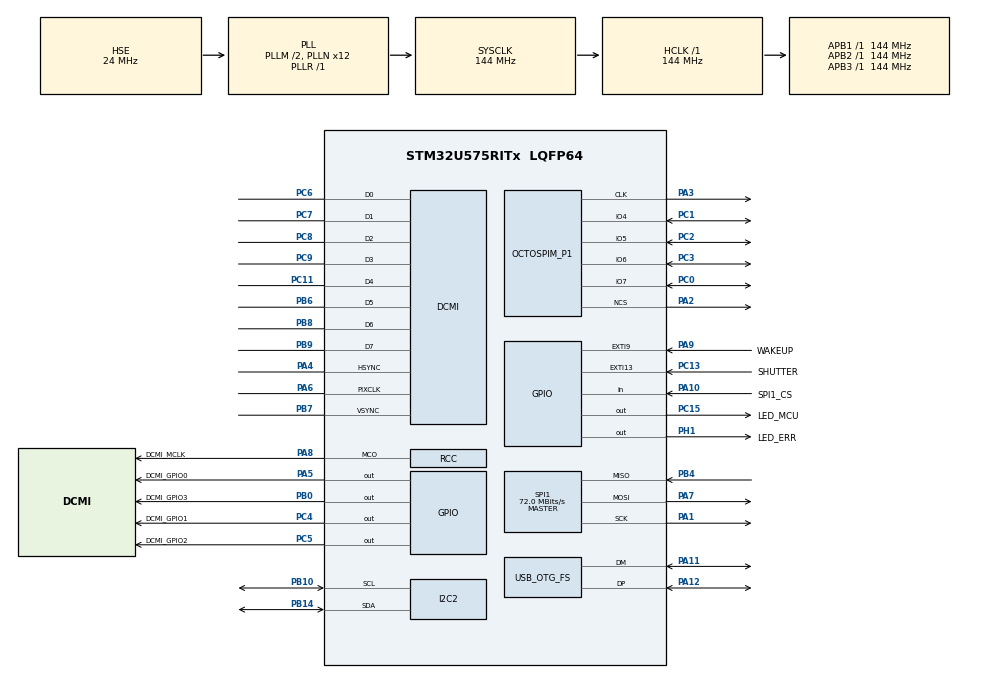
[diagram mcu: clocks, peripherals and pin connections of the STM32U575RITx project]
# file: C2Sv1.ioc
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CORTEX_M33_NS.userName=CORTEX_M33
DCMI.HSPolarity=DCMI_HSPOLARITY_LOW
DCMI.JPEGMode=DCMI_JPEG_DISABLE
DCMI.PCKPolarity=DCMI_PCKPOLARITY_RISING
DCMI.VSPolarity=DCMI_VSPOLARITY_HIGH
GPDMA1.ChannelPRIV_GPDMACH0=DMA_CHANNEL_NPRIV
GPDMA1.LINKALLOCATEDPORT_GPDMACH0=DMA_LINK_ALLOCATED_PORT0
GPDMA1.LINKEDLISTMODE_GPDMACH0=DMA_LINKEDLIST_CIRCULAR
GPDMA1.PRIORITY_LL_GPDMACH0=DMA_HIGH_PRIORITY
GPDMA1.RECAP_GPDMACH0=DMA_REQUEST_DCMI
I2C2.NoStretchMode=I2C_NOSTRETCH_ENABLE
I2C2.Timing=0x20B0D9FF
Linkedlist.MDMA_Channel0.GP_SW.0.BlkHWRequest=DMA_BREQ_SINGLE_BURST
Linkedlist.MDMA_Channel0.GP_SW.0.DataHandling=NONE
Linkedlist.MDMA_Channel0.GP_SW.0.DataSize=0
Linkedlist.MDMA_Channel0.GP_SW.0.DestBurstLength=1
Linkedlist.MDMA_Channel0.GP_SW.0.DestDataWidth=DMA_DEST_DATAWIDTH_WORD
Linkedlist.MDMA_Channel0.GP_SW.0.DestInc=DMA_DINC_INCREMENTED
Linkedlist.MDMA_Channel0.GP_SW.0.Direction=DMA_PERIPH_TO_MEMORY
Linkedlist.MDMA_Channel0.GP_SW.0.DstAddress=0
Linkedlist.MDMA_Channel0.GP_SW.0.Instance=MDMA_Channel0
Linkedlist.MDMA_Channel0.GP_SW.0.LL_CIRCULARNODE=DCMI_Node1
Linkedlist.MDMA_Channel0.GP_SW.0.LL_MASTERDMA=GPDMA
Linkedlist.MDMA_Channel0.GP_SW.0.LL_NAME=DCMIQueue
Linkedlist.MDMA_Channel0.GP_SW.0.LL_TYPE=CIRCULAR
Linkedlist.MDMA_Channel0.GP_SW.0.NODE_NAME=DCMI_Node1
Linkedlist.MDMA_Channel0.GP_SW.0.Requestforcodegen=GPDMA1_REQUEST_DCMI
Linkedlist.MDMA_Channel0.GP_SW.0.SrcAddress=0
Linkedlist.MDMA_Channel0.GP_SW.0.SrcBurstLength=1
Linkedlist.MDMA_Channel0.GP_SW.0.SrcDataWidth=DMA_SRC_DATAWIDTH_WORD
Linkedlist.MDMA_Channel0.GP_SW.0.SrcInc=DMA_SINC_FIXED
Linkedlist.MDMA_Channel0.GP_SW.0.TransferAllocatedPortDest=DMA_DEST_ALLOCATED_PORT0
Linkedlist.MDMA_Channel0.GP_SW.0.TransferAllocatedPortSrc=DMA_SRC_ALLOCATED_PORT0
Linkedlist.MDMA_Channel0.GP_SW.0.TransferEventMode=DMA_TCEM_EACH_LL_ITEM_TRANSFER
Linkedlist.MDMA_Channel0.GP_SW.0.TriggerPolarity=DMA_TRIG_POLARITY_MASKED
Linkedlist.MDMA_Channel0.GP_SW.1.BlkHWRequest=DMA_BREQ_SINGLE_BURST
Linkedlist.MDMA_Channel0.GP_SW.1.DataHandling=NONE
Linkedlist.MDMA_Channel0.GP_SW.1.DataSize=0
Linkedlist.MDMA_Channel0.GP_SW.1.DestBurstLength=1
Linkedlist.MDMA_Channel0.GP_SW.1.DestDataWidth=DMA_DEST_DATAWIDTH_WORD
Linkedlist.MDMA_Channel0.GP_SW.1.DestInc=DMA_DINC_INCREMENTED
Linkedlist.MDMA_Channel0.GP_SW.1.Direction=DMA_PERIPH_TO_MEMORY
Linkedlist.MDMA_Channel0.GP_SW.1.DstAddress=0
Linkedlist.MDMA_Channel0.GP_SW.1.Instance=MDMA_Channel0
Linkedlist.MDMA_Channel0.GP_SW.1.LL_CIRCULARNODE=DCMI_Node1
Linkedlist.MDMA_Channel0.GP_SW.1.LL_MASTERDMA=GPDMA
Linkedlist.MDMA_Channel0.GP_SW.1.LL_NAME=DCMIQueue
Linkedlist.MDMA_Channel0.GP_SW.1.LL_TYPE=CIRCULAR
Linkedlist.MDMA_Channel0.GP_SW.1.NODE_NAME=DCMI_Node2
Linkedlist.MDMA_Channel0.GP_SW.1.Requestforcodegen=GPDMA1_REQUEST_DCMI
Linkedlist.MDMA_Channel0.GP_SW.1.SrcAddress=0
Linkedlist.MDMA_Channel0.GP_SW.1.SrcBurstLength=1
Linkedlist.MDMA_Channel0.GP_SW.1.SrcDataWidth=DMA_SRC_DATAWIDTH_WORD
Linkedlist.MDMA_Channel0.GP_SW.1.SrcInc=DMA_SINC_FIXED
Linkedlist.MDMA_Channel0.GP_SW.1.TransferAllocatedPortDest=DMA_DEST_ALLOCATED_PORT0
Linkedlist.MDMA_Channel0.GP_SW.1.TransferAllocatedPortSrc=DMA_SRC_ALLOCATED_PORT0
Linkedlist.MDMA_Channel0.GP_SW.1.TransferEventMode=DMA_TCEM_EACH_LL_ITEM_TRANSFER
Linkedlist.MDMA_Channel0.GP_SW.1.TriggerPolarity=DMA_TRIG_POLARITY_MASKED
Linkedlist.MDMA_Channel0.Request0=GP_SW
Linkedlist.MDMA_Channel0.Request1=GP_SW
Linkedlist.MDMA_Channel0.RequestsNb=2
Linkedlist.RequestSet0=MDMA_Channel0
Linkedlist.RequestSetsNb=1
Mcu.Family=STM32U5
Mcu.Name=STM32U575RITx
Mcu.Package=LQFP64
NVIC.DCMI_PSSI_IRQn=true\:0\:0\:false\:false\:true\:false\:true\:true\:true
NVIC.EXTI13_IRQn=true\:0\:0\:false\:false\:true\:false\:true\:true\:true
NVIC.EXTI9_IRQn=true\:0\:0\:false\:false\:true\:false\:true\:true\:true
NVIC.GPDMA1_Channel0_IRQn=true\:0\:0\:false\:false\:true\:true\:false\:true\:true
NVIC.OTG_FS_IRQn=true\:0\:0\:false\:false\:true\:false\:true\:true\:true
NVIC.PriorityGroup=NVIC_PRIORITYGROUP_4
NVIC.TIM17_IRQn=true\:15\:0\:false\:false\:true\:false\:false\:true\:true
NVIC.TimeBase=TIM17_IRQn
NVIC.TimeBaseIP=TIM17
OCTOSPI1.ChipSelectHighTime=3
OCTOSPI1.ClockPrescaler=2
OCTOSPI1.DeviceSize=24
OCTOSPI1.SampleShifting=HAL_OSPI_SAMPLE_SHIFTING_HALFCYCLE
PA1.Mode=Full_Duplex_Master
PA1.Signal=SPI1_SCK
PA10.GPIO_Label=SPI1_CS
PA10.Signal=GPIO_Input
PA11.GPIO_PuPd=GPIO_NOPULL
PA11.Mode=Device_Only
PA11.Signal=USB_OTG_FS_DM
PA12.GPIO_PuPd=GPIO_NOPULL
PA12.Mode=Device_Only
PA12.Signal=USB_OTG_FS_DP
PA13\ (JTMS/SWDIO).Mode=Serial_Wire
PA13\ (JTMS/SWDIO).Signal=DEBUG_JTMS-SWDIO
PA14\ (JTCK/SWCLK).Mode=Serial_Wire
PA14\ (JTCK/SWCLK).Signal=DEBUG_JTCK-SWCLK
PA2.Mode=OCTOSPI1_Port1_NCS
PA2.Signal=OCTOSPIM_P1_NCS
PA3.Mode=O1_P1_CLK
PA3.Signal=OCTOSPIM_P1_CLK
PA4.GPIO_PuPd=GPIO_PULLDOWN
PA4.GPIO_Speed=GPIO_SPEED_FREQ_VERY_HIGH
PA4.Mode=Slave_8_bits_External_Synchro
PA4.Signal=DCMI_HSYNC
PA5.GPIO_Label=DCMI_GPIO0
PA5.Signal=GPIO_Output
PA6.GPIO_PuPd=GPIO_PULLDOWN
PA6.GPIO_Speed=GPIO_SPEED_FREQ_VERY_HIGH
PA6.Mode=Slave_8_bits_External_Synchro
PA6.Signal=DCMI_PIXCLK
PA7.Mode=Full_Duplex_Master
PA7.Signal=SPI1_MOSI
PA8.GPIO_Label=DCMI_MCLK
PA8.Mode=Clock-out
PA8.Signal=RCC_MCO
PA9.GPIO_Label=WAKEUP
PA9.GPIO_ModeDefaultEXTI=GPIO_MODE_IT_RISING_FALLING
PA9.Signal=GPXTI9
PB0.GPIO_Label=DCMI_GPIO3
PB0.Signal=GPIO_Output
PB10.GPIO_Pu=GPIO_PULLUP
PB10.Mode=I2C
PB10.Signal=I2C2_SCL
PB14.GPIO_Pu=GPIO_PULLUP
PB14.Mode=I2C
PB14.Signal=I2C2_SDA
PB4\ (NJTRST).Mode=Full_Duplex_Master
PB4\ (NJTRST).Signal=SPI1_MISO
PB6.GPIO_PuPd=GPIO_PULLDOWN
PB6.GPIO_Speed=GPIO_SPEED_FREQ_VERY_HIGH
PB6.Mode=Slave_8_bits_External_Synchro
PB6.Signal=DCMI_D5
PB7.GPIO_PuPd=GPIO_PULLDOWN
PB7.GPIO_Speed=GPIO_SPEED_FREQ_VERY_HIGH
PB7.Mode=Slave_8_bits_External_Synchro
PB7.Signal=DCMI_VSYNC
PB8.GPIO_PuPd=GPIO_PULLDOWN
PB8.GPIO_Speed=GPIO_SPEED_FREQ_VERY_HIGH
PB8.Mode=Slave_8_bits_External_Synchro
PB8.Signal=DCMI_D6
PB9.GPIO_PuPd=GPIO_PULLDOWN
PB9.GPIO_Speed=GPIO_SPEED_FREQ_VERY_HIGH
PB9.Mode=Slave_8_bits_External_Synchro
PB9.Signal=DCMI_D7
PC0.Mode=OCTOSPI1_IOL_Port1H
PC0.Signal=OCTOSPIM_P1_IO7
PC1.Mode=OCTOSPI1_IOL_Port1H
PC1.Signal=OCTOSPIM_P1_IO4
PC11.GPIO_PuPd=GPIO_PULLDOWN
PC11.GPIO_Speed=GPIO_SPEED_FREQ_VERY_HIGH
PC11.Mode=Slave_8_bits_External_Synchro
PC11.Signal=DCMI_D4
PC13.GPIO_Label=SHUTTER
PC13.Signal=GPXTI13
PC14-OSC32_IN\ (PC14).Mode=LSE-External-Clock-Source
PC14-OSC32_IN\ (PC14).Signal=RCC_OSC32_IN
PC15-OSC32_OUT\ (PC15).GPIO_Label=LED_MCU
PC15-OSC32_OUT\ (PC15).Signal=GPIO_Output
PC2.Mode=OCTOSPI1_IOL_Port1H
PC2.Signal=OCTOSPIM_P1_IO5
PC3.Mode=OCTOSPI1_IOL_Port1H
PC3.Signal=OCTOSPIM_P1_IO6
PC4.GPIO_Label=DCMI_GPIO1
PC4.Signal=GPIO_Output
PC5.GPIO_Label=DCMI_GPIO2
PC5.Signal=GPIO_Output
PC6.GPIO_PuPd=GPIO_PULLDOWN
PC6.GPIO_Speed=GPIO_SPEED_FREQ_VERY_HIGH
PC6.Mode=Slave_8_bits_External_Synchro
PC6.Signal=DCMI_D0
PC7.GPIO_PuPd=GPIO_PULLDOWN
PC7.GPIO_Speed=GPIO_SPEED_FREQ_VERY_HIGH
PC7.Mode=Slave_8_bits_External_Synchro
PC7.Signal=DCMI_D1
PC8.GPIO_PuPd=GPIO_PULLDOWN
PC8.GPIO_Speed=GPIO_SPEED_FREQ_VERY_HIGH
PC8.Mode=Slave_8_bits_External_Synchro
PC8.Signal=DCMI_D2
PC9.GPIO_PuPd=GPIO_PULLDOWN
PC9.GPIO_Speed=GPIO_SPEED_FREQ_VERY_HIGH
PC9.Mode=Slave_8_bits_External_Synchro
PC9.Signal=DCMI_D3
PH0-OSC_IN\ (PH0).Mode=HSE-External-Clock-Source
PH0-OSC_IN\ (PH0).Signal=RCC_OSC_IN
PH1-OSC_OUT\ (PH1).GPIO_Label=LED_ERR
PH1-OSC_OUT\ (PH1).Signal=GPIO_Output
ProjectManager.HeapSize=0x200
ProjectManager.StackSize=0x400
ProjectManager.TargetToolchain=STM32CubeIDE
RCC.ADCFreq_Value=16000000
RCC.AHBFreq_Value=144000000
RCC.APB1Freq_Value=144000000
RCC.APB1TimFreq_Value=144000000
RCC.APB2Freq_Value=144000000
RCC.APB2TimFreq_Value=144000000
RCC.APB3Freq_Value=144000000
RCC.CK48CLockSelection=RCC_CLK48CLKSOURCE_PLL1
RCC.CortexFreq_Value=144000000
RCC.EPOD_VALUE=24000000
RCC.EnbaleCSS=true
RCC.HCLKFreq_Value=144000000
RCC.HSE_VALUE=24000000
RCC.HSI48_VALUE=48000000
RCC.HSI_VALUE=16000000
RCC.LSE_VALUE=32768
RCC.LSIDIV_VALUE=32000
RCC.MSIClockRange=RCC_MSIRANGE_0
RCC.MSI_VALUE=48000000
RCC.OCTOSPIMCLockSelection=RCC_OSPICLKSOURCE_PLL2
RCC.PLL1Q=3
RCC.PLL1R=1
RCC.PLL2FRACN=0
RCC.PLL2M=3
RCC.PLL2N=25
RCC.PLL3FRACN=0
RCC.PLLFRACN=0
RCC.PLLM=2
RCC.PLLN=12
RCC.PLLSourceVirtual=RCC_PLLSOURCE_HSE
RCC.RCC_MCO1SourceVirtual=RCC_MCO1SOURCE_HSE
RCC.SYSCLKFreq_VALUE=144000000
RCC.SYSCLKSource=RCC_SYSCLKSOURCE_PLLCLK
RCC.USBFreq_Value=48000000
RCC.VCOOutputFreq_Value=144000000
SPI1.CalculateBaudRate=72.0 MBits/s
SPI1.Direction=SPI_DIRECTION_2LINES
SPI1.Mode=SPI_MODE_MASTER
SPI1.VirtualType=VM_MASTER
THREADX.TX_APP_MEM_POOL_SIZE=1024*12
USB_OTG_FS.VirtualMode=Device_Only
VP_GPDMA1_VS_GPDMACH0.Mode=LINKEDLIST_GPDMACH0
VP_ICACHE_VS_ENABLE_ICACHE_MEMORY.Mode=Memoryregions
VP_ICACHE_VS_ICACHE.Mode=DefaultMode
VP_LPBAMQUEUE_VS_QUEUE.Mode=QUEUEMODE
VP_LPBAM_VS_SIG1.Mode=SmartRun
VP_LPBAM_VS_SIG4.Mode=LPDMA1
VP_MEMORYMAP_VS_MEMORYMAP.Mode=CurAppReg
VP_OCTOSPI1_VS_quad.Mode=quad_mode
VP_PWR_VS_SECSignals.Mode=Security/Privilege
VP_SYS_VS_tim17.Mode=TIM17
VP_THREADX_VS_RTOSJjThreadXJjCoreJjDefault.Mode=Core_Default
board=custom

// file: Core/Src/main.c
/* USER CODE BEGIN Header */
/**
  ******************************************************************************
  * @file           : main.c
  * @brief          : Main program body
  ******************************************************************************
  * @attention
  *
  * Copyright (c) 2026 STMicroelectronics.
  * All rights reserved.
  *
  * This software is licensed under terms that can be found in the LICENSE file
  * in the root directory of this software component.
  * If no LICENSE file comes with this software, it is provided AS-IS.
  *
  ******************************************************************************
  */
/* USER CODE END Header */
#include "app_threadx.h"
#include "main.h"

DCMI_HandleTypeDef hdcmi;

DMA_HandleTypeDef handle_GPDMA1_Channel0;

I2C_HandleTypeDef hi2c2;

OSPI_HandleTypeDef hospi1;

SPI_HandleTypeDef hspi1;

PCD_HandleTypeDef hpcd_USB_OTG_FS;

/* USER CODE BEGIN PV */

// QSPI
QSPI_HandleTypeDef QSPI_Memory;
OSPI_RegularCmdTypeDef sCommand;

// Interrupt
volatile bool c2s_should_sleep = 0;

// Camera
ALIGN_32BYTES(uint32_t pBuffer[LL_MAX_NODE_SIZE/4*2]);//__attribute__((section(".sram3"))); 	// Force the buffer into SRAM3
ALIGN_32BYTES(uint32_t bufferC[DB_SIZE_WORDS]);
volatile uint8_t FrameProcessed = 0;													// Image captured to RAM (1); not (0)
volatile uint32_t processedRows = 0;

/* USER CODE END PV */

void SystemClock_Config(void);
static void MX_GPIO_Init(void);
static void MX_DCMI_Init(void);
static void MX_I2C2_Init(void);
static void MX_OCTOSPI1_Init(void);
static void MX_USB_OTG_FS_PCD_Init(void);
static void MX_SPI1_Init(void);
static void MX_ICACHE_Init(void);

int main(void)
{

  /* MCU Configuration--------------------------------------------------------*/

  /* Reset of all peripherals, Initializes the Flash interface and the Systick. */
  HAL_Init();

  /* Configure the system clock */
  SystemClock_Config();

  /* Initialize all configured peripherals */
  MX_GPIO_Init();
  MX_GPDMA1_Init();
  MX_DCMI_Init();
  MX_I2C2_Init();
  MX_OCTOSPI1_Init();
  MX_USB_OTG_FS_PCD_Init();
  MX_SPI1_Init();
  MX_ICACHE_Init();
  /* USER CODE BEGIN 2 */

//  while(1)
//  {
//		if (c2s_should_sleep)
//		{
//			// ENTER SLEEP/STOP HERE
//			HAL_GPIO_WritePin(LED_MCU_GPIO_Port, LED_MCU_Pin, GPIO_PIN_SET); // Turn on MCU LED
//			//tx_thread_sleep_ms(200);
//			HAL_SuspendTick();
//			HAL_PWR_EnterSTOPMode(PWR_MAINREGULATOR_ON, PWR_STOPENTRY_WFI);		// STOP0
//			//HAL_PWR_EnterSLEEPMode(PWR_MAINREGULATOR_ON, PWR_SLEEPENTRY_WFI);	// SLEEP
//
//			// --- CPU WAKES UP ---
//			SystemClock_Config();
//			HAL_ResumeTick();
//			HAL_GPIO_WritePin(LED_MCU_GPIO_Port, LED_MCU_Pin, GPIO_PIN_RESET);
//		}
//  }

  /* USER CODE END 2 */

  MX_ThreadX_Init();

  /* We should never get here as control is now taken by the scheduler */

  /* Infinite loop */
  while (1)
  {

  }
}

void SystemClock_Config(void)
{
  RCC_OscInitTypeDef RCC_OscInitStruct = {0};
  RCC_ClkInitTypeDef RCC_ClkInitStruct = {0};

  /** Configure the main internal regulator output voltage
  */
  if (HAL_PWREx_ControlVoltageScaling(PWR_REGULATOR_VOLTAGE_SCALE1) != HAL_OK)
  {
    Error_Handler();
  }

  /** Initializes the CPU, AHB and APB buses clocks
  */
  RCC_OscInitStruct.OscillatorType = RCC_OSCILLATORTYPE_HSE|RCC_OSCILLATORTYPE_MSI;
  RCC_OscInitStruct.HSEState = RCC_HSE_BYPASS;
  RCC_OscInitStruct.MSIState = RCC_MSI_ON;
  RCC_OscInitStruct.MSICalibrationValue = RCC_MSICALIBRATION_DEFAULT;
  RCC_OscInitStruct.MSIClockRange = RCC_MSIRANGE_0;
  RCC_OscInitStruct.PLL.PLLState = RCC_PLL_ON;
  RCC_OscInitStruct.PLL.PLLSource = RCC_PLLSOURCE_HSE;
  RCC_OscInitStruct.PLL.PLLMBOOST = RCC_PLLMBOOST_DIV2;
  RCC_OscInitStruct.PLL.PLLM = 2;
  RCC_OscInitStruct.PLL.PLLN = 12;
  RCC_OscInitStruct.PLL.PLLP = 2;
  RCC_OscInitStruct.PLL.PLLQ = 3;
  RCC_OscInitStruct.PLL.PLLR = 1;
  RCC_OscInitStruct.PLL.PLLRGE = RCC_PLLVCIRANGE_1;
  RCC_OscInitStruct.PLL.PLLFRACN = 0;
  if (HAL_RCC_OscConfig(&RCC_OscInitStruct) != HAL_OK)
  {
    Error_Handler();
  }

  /** Initializes the CPU, AHB and APB buses clocks
  */
  RCC_ClkInitStruct.ClockType = RCC_CLOCKTYPE_HCLK|RCC_CLOCKTYPE_SYSCLK
                              |RCC_CLOCKTYPE_PCLK1|RCC_CLOCKTYPE_PCLK2
                              |RCC_CLOCKTYPE_PCLK3;
  RCC_ClkInitStruct.SYSCLKSource = RCC_SYSCLKSOURCE_PLLCLK;
  RCC_ClkInitStruct.AHBCLKDivider = RCC_SYSCLK_DIV1;
  RCC_ClkInitStruct.APB1CLKDivider = RCC_HCLK_DIV1;
  RCC_ClkInitStruct.APB2CLKDivider = RCC_HCLK_DIV1;
  RCC_ClkInitStruct.APB3CLKDivider = RCC_HCLK_DIV1;

  if (HAL_RCC_ClockConfig(&RCC_ClkInitStruct, FLASH_LATENCY_4) != HAL_OK)
  {
    Error_Handler();
  }

  /** MCO configuration
  */
  HAL_RCC_MCOConfig(RCC_MCO1, RCC_MCO1SOURCE_HSE, RCC_MCODIV_1);

  /** Enables the Clock Security System
  */
  HAL_RCC_EnableCSS();
}

static void MX_DCMI_Init(void)
{

  hdcmi.Instance = DCMI;
  hdcmi.Init.SynchroMode = DCMI_SYNCHRO_HARDWARE;
  hdcmi.Init.PCKPolarity = DCMI_PCKPOLARITY_RISING;
  hdcmi.Init.VSPolarity = DCMI_VSPOLARITY_HIGH;
  hdcmi.Init.HSPolarity = DCMI_HSPOLARITY_LOW;
  hdcmi.Init.CaptureRate = DCMI_CR_ALL_FRAME;
  hdcmi.Init.ExtendedDataMode = DCMI_EXTEND_DATA_8B;
  hdcmi.Init.JPEGMode = DCMI_JPEG_DISABLE;
  hdcmi.Init.ByteSelectMode = DCMI_BSM_ALL;
  hdcmi.Init.ByteSelectStart = DCMI_OEBS_ODD;
  hdcmi.Init.LineSelectMode = DCMI_LSM_ALL;
  hdcmi.Init.LineSelectStart = DCMI_OELS_ODD;
  if (HAL_DCMI_Init(&hdcmi) != HAL_OK)
  {
    Error_Handler();
  }

}

void MX_GPDMA1_Init(void)
{

  /* Peripheral clock enable */
  __HAL_RCC_GPDMA1_CLK_ENABLE();

  /* GPDMA1 interrupt Init */
    HAL_NVIC_SetPriority(GPDMA1_Channel0_IRQn, 0, 0);
    HAL_NVIC_EnableIRQ(GPDMA1_Channel0_IRQn);

  handle_GPDMA1_Channel0.Instance = GPDMA1_Channel0;
  handle_GPDMA1_Channel0.InitLinkedList.Priority = DMA_HIGH_PRIORITY;
  handle_GPDMA1_Channel0.InitLinkedList.LinkStepMode = DMA_LSM_FULL_EXECUTION;
  handle_GPDMA1_Channel0.InitLinkedList.LinkAllocatedPort = DMA_LINK_ALLOCATED_PORT0;
  handle_GPDMA1_Channel0.InitLinkedList.TransferEventMode = DMA_TCEM_LAST_LL_ITEM_TRANSFER;
  handle_GPDMA1_Channel0.InitLinkedList.LinkedListMode = DMA_LINKEDLIST_CIRCULAR;
  if (HAL_DMAEx_List_Init(&handle_GPDMA1_Channel0) != HAL_OK)
  {
    Error_Handler();
  }
  if (HAL_DMA_ConfigChannelAttributes(&handle_GPDMA1_Channel0, DMA_CHANNEL_NPRIV) != HAL_OK)
  {
    Error_Handler();
  }

}

static void MX_I2C2_Init(void)
{

  hi2c2.Instance = I2C2;
  hi2c2.Init.Timing = 0x20B0D9FF;
  hi2c2.Init.OwnAddress1 = 0;
  hi2c2.Init.AddressingMode = I2C_ADDRESSINGMODE_7BIT;
  hi2c2.Init.DualAddressMode = I2C_DUALADDRESS_DISABLE;
  hi2c2.Init.OwnAddress2 = 0;
  hi2c2.Init.OwnAddress2Masks = I2C_OA2_NOMASK;
  hi2c2.Init.GeneralCallMode = I2C_GENERALCALL_DISABLE;
  hi2c2.Init.NoStretchMode = I2C_NOSTRETCH_ENABLE;
  if (HAL_I2C_Init(&hi2c2) != HAL_OK)
  {
    Error_Handler();
  }

  /** Configure Analogue filter
  */
  if (HAL_I2CEx_ConfigAnalogFilter(&hi2c2, I2C_ANALOGFILTER_ENABLE) != HAL_OK)
  {
    Error_Handler();
  }

  /** Configure Digital filter
  */
  if (HAL_I2CEx_ConfigDigitalFilter(&hi2c2, 0) != HAL_OK)
  {
    Error_Handler();
  }

}

static void MX_ICACHE_Init(void)
{

  /** Enable instruction cache (default 2-ways set associative cache)
  */
  if (HAL_ICACHE_Enable() != HAL_OK)
  {
    Error_Handler();
  }

}

static void MX_OCTOSPI1_Init(void)
{

  OSPIM_CfgTypeDef sOspiManagerCfg = {0};

  /* OCTOSPI1 parameter configuration*/
  hospi1.Instance = OCTOSPI1;
  hospi1.Init.FifoThreshold = 1;
  hospi1.Init.DualQuad = HAL_OSPI_DUALQUAD_DISABLE;
  hospi1.Init.MemoryType = HAL_OSPI_MEMTYPE_MICRON;
  hospi1.Init.DeviceSize = 24;
  hospi1.Init.ChipSelectHighTime = 3;
  hospi1.Init.FreeRunningClock = HAL_OSPI_FREERUNCLK_DISABLE;
  hospi1.Init.ClockMode = HAL_OSPI_CLOCK_MODE_0;
  hospi1.Init.WrapSize = HAL_OSPI_WRAP_NOT_SUPPORTED;
  hospi1.Init.ClockPrescaler = 2;
  hospi1.Init.SampleShifting = HAL_OSPI_SAMPLE_SHIFTING_HALFCYCLE;
  hospi1.Init.DelayHoldQuarterCycle = HAL_OSPI_DHQC_DISABLE;
  hospi1.Init.ChipSelectBoundary = 0;
  hospi1.Init.DelayBlockBypass = HAL_OSPI_DELAY_BLOCK_BYPASSED;
  hospi1.Init.MaxTran = 0;
  hospi1.Init.Refresh = 0;
  if (HAL_OSPI_Init(&hospi1) != HAL_OK)
  {
    Error_Handler();
  }
  sOspiManagerCfg.ClkPort = 1;
  sOspiManagerCfg.NCSPort = 1;
  sOspiManagerCfg.IOLowPort = HAL_OSPIM_IOPORT_1_HIGH;
  if (HAL_OSPIM_Config(&hospi1, &sOspiManagerCfg, HAL_OSPI_TIMEOUT_DEFAULT_VALUE) != HAL_OK)
  {
    Error_Handler();
  }

}

static void MX_SPI1_Init(void)
{

  SPI_AutonomousModeConfTypeDef HAL_SPI_AutonomousMode_Cfg_Struct = {0};

  /* SPI1 parameter configuration*/
  hspi1.Instance = SPI1;
  hspi1.Init.Mode = SPI_MODE_MASTER;
  hspi1.Init.Direction = SPI_DIRECTION_2LINES;
  hspi1.Init.DataSize = SPI_DATASIZE_4BIT;
  hspi1.Init.CLKPolarity = SPI_POLARITY_LOW;
  hspi1.Init.CLKPhase = SPI_PHASE_1EDGE;
  hspi1.Init.NSS = SPI_NSS_SOFT;
  hspi1.Init.BaudRatePrescaler = SPI_BAUDRATEPRESCALER_2;
  hspi1.Init.FirstBit = SPI_FIRSTBIT_MSB;
  hspi1.Init.TIMode = SPI_TIMODE_DISABLE;
  hspi1.Init.CRCCalculation = SPI_CRCCALCULATION_DISABLE;
  hspi1.Init.CRCPolynomial = 0x7;
  hspi1.Init.NSSPMode = SPI_NSS_PULSE_ENABLE;
  hspi1.Init.NSSPolarity = SPI_NSS_POLARITY_LOW;
  hspi1.Init.FifoThreshold = SPI_FIFO_THRESHOLD_01DATA;
  hspi1.Init.MasterSSIdleness = SPI_MASTER_SS_IDLENESS_00CYCLE;
  hspi1.Init.MasterInterDataIdleness = SPI_MASTER_INTERDATA_IDLENESS_00CYCLE;
  hspi1.Init.MasterReceiverAutoSusp = SPI_MASTER_RX_AUTOSUSP_DISABLE;
  hspi1.Init.MasterKeepIOState = SPI_MASTER_KEEP_IO_STATE_DISABLE;
  hspi1.Init.IOSwap = SPI_IO_SWAP_DISABLE;
  hspi1.Init.ReadyMasterManagement = SPI_RDY_MASTER_MANAGEMENT_INTERNALLY;
  hspi1.Init.ReadyPolarity = SPI_RDY_POLARITY_HIGH;
  if (HAL_SPI_Init(&hspi1) != HAL_OK)
  {
    Error_Handler();
  }
  HAL_SPI_AutonomousMode_Cfg_Struct.TriggerState = SPI_AUTO_MODE_DISABLE;
  HAL_SPI_AutonomousMode_Cfg_Struct.TriggerSelection = SPI_GRP1_GPDMA_CH0_TCF_TRG;
  HAL_SPI_AutonomousMode_Cfg_Struct.TriggerPolarity = SPI_TRIG_POLARITY_RISING;
  if (HAL_SPIEx_SetConfigAutonomousMode(&hspi1, &HAL_SPI_AutonomousMode_Cfg_Struct) != HAL_OK)
  {
    Error_Handler();
  }

}

static void MX_USB_OTG_FS_PCD_Init(void)
{

  hpcd_USB_OTG_FS.Instance = USB_OTG_FS;
  hpcd_USB_OTG_FS.Init.dev_endpoints = 6;
  hpcd_USB_OTG_FS.Init.speed = PCD_SPEED_FULL;
  hpcd_USB_OTG_FS.Init.phy_itface = PCD_PHY_EMBEDDED;
  hpcd_USB_OTG_FS.Init.Sof_enable = DISABLE;
  hpcd_USB_OTG_FS.Init.low_power_enable = DISABLE;
  hpcd_USB_OTG_FS.Init.lpm_enable = DISABLE;
  hpcd_USB_OTG_FS.Init.battery_charging_enable = DISABLE;
  hpcd_USB_OTG_FS.Init.use_dedicated_ep1 = DISABLE;
  hpcd_USB_OTG_FS.Init.vbus_sensing_enable = DISABLE;
  hpcd_USB_OTG_FS.Init.dma_enable = DISABLE;
  if (HAL_PCD_Init(&hpcd_USB_OTG_FS) != HAL_OK)
  {
    Error_Handler();
  }

}

static void MX_GPIO_Init(void)
{
  GPIO_InitTypeDef GPIO_InitStruct = {0};

  /* GPIO Ports Clock Enable */
  __HAL_RCC_GPIOC_CLK_ENABLE();
  __HAL_RCC_GPIOH_CLK_ENABLE();
  __HAL_RCC_GPIOA_CLK_ENABLE();
  __HAL_RCC_GPIOB_CLK_ENABLE();
  __HAL_RCC_GPIOD_CLK_ENABLE();

  /*Configure GPIO pin Output Level */
  HAL_GPIO_WritePin(GPIOC, LED_MCU_Pin|DCMI_GPIO1_Pin|DCMI_GPIO2_Pin, GPIO_PIN_RESET);

  /*Configure GPIO pin Output Level */
  HAL_GPIO_WritePin(LED_ERR_GPIO_Port, LED_ERR_Pin, GPIO_PIN_RESET);

  /*Configure GPIO pin Output Level */
  HAL_GPIO_WritePin(DCMI_GPIO0_GPIO_Port, DCMI_GPIO0_Pin, GPIO_PIN_RESET);

  /*Configure GPIO pin Output Level */
  HAL_GPIO_WritePin(DCMI_GPIO3_GPIO_Port, DCMI_GPIO3_Pin, GPIO_PIN_RESET);

  /*Configure GPIO pin : SHUTTER_Pin */
  GPIO_InitStruct.Pin = SHUTTER_Pin;
  GPIO_InitStruct.Mode = GPIO_MODE_IT_RISING;
  GPIO_InitStruct.Pull = GPIO_NOPULL;
  HAL_GPIO_Init(SHUTTER_GPIO_Port, &GPIO_InitStruct);

  /*Configure GPIO pins : LED_MCU_Pin DCMI_GPIO1_Pin DCMI_GPIO2_Pin */
  GPIO_InitStruct.Pin = LED_MCU_Pin|DCMI_GPIO1_Pin|DCMI_GPIO2_Pin;
  GPIO_InitStruct.Mode = GPIO_MODE_OUTPUT_PP;
  GPIO_InitStruct.Pull = GPIO_NOPULL;
  GPIO_InitStruct.Speed = GPIO_SPEED_FREQ_LOW;
  HAL_GPIO_Init(GPIOC, &GPIO_InitStruct);

  /*Configure GPIO pin : LED_ERR_Pin */
  GPIO_InitStruct.Pin = LED_ERR_Pin;
  GPIO_InitStruct.Mode = GPIO_MODE_OUTPUT_PP;
  GPIO_InitStruct.Pull = GPIO_NOPULL;
  GPIO_InitStruct.Speed = GPIO_SPEED_FREQ_LOW;
  HAL_GPIO_Init(LED_ERR_GPIO_Port, &GPIO_InitStruct);

  /*Configure GPIO pins : PA0 PA15 */
  GPIO_InitStruct.Pin = GPIO_PIN_0|GPIO_PIN_15;
  GPIO_InitStruct.Mode = GPIO_MODE_ANALOG;
  GPIO_InitStruct.Pull = GPIO_NOPULL;
  HAL_GPIO_Init(GPIOA, &GPIO_InitStruct);

  /*Configure GPIO pin : DCMI_GPIO0_Pin */
  GPIO_InitStruct.Pin = DCMI_GPIO0_Pin;
  GPIO_InitStruct.Mode = GPIO_MODE_OUTPUT_PP;
  GPIO_InitStruct.Pull = GPIO_NOPULL;
  GPIO_InitStruct.Speed = GPIO_SPEED_FREQ_LOW;
  HAL_GPIO_Init(DCMI_GPIO0_GPIO_Port, &GPIO_InitStruct);

  /*Configure GPIO pin : DCMI_GPIO3_Pin */
  GPIO_InitStruct.Pin = DCMI_GPIO3_Pin;
  GPIO_InitStruct.Mode = GPIO_MODE_OUTPUT_PP;
  GPIO_InitStruct.Pull = GPIO_NOPULL;
  GPIO_InitStruct.Speed = GPIO_SPEED_FREQ_LOW;
  HAL_GPIO_Init(DCMI_GPIO3_GPIO_Port, &GPIO_InitStruct);

  /*Configure GPIO pins : PB1 PB2 PB12 PB13
                           PB15 PB3 PB5 */
  GPIO_InitStruct.Pin = GPIO_PIN_1|GPIO_PIN_2|GPIO_PIN_12|GPIO_PIN_13
                          |GPIO_PIN_15|GPIO_PIN_3|GPIO_PIN_5;
  GPIO_InitStruct.Mode = GPIO_MODE_ANALOG;
  GPIO_InitStruct.Pull = GPIO_NOPULL;
  HAL_GPIO_Init(GPIOB, &GPIO_InitStruct);

  /*Configure GPIO pin : DCMI_MCLK_Pin */
  GPIO_InitStruct.Pin = DCMI_MCLK_Pin;
  GPIO_InitStruct.Mode = GPIO_MODE_AF_PP;
  GPIO_InitStruct.Pull = GPIO_NOPULL;
  GPIO_InitStruct.Speed = GPIO_SPEED_FREQ_HIGH;
  GPIO_InitStruct.Alternate = GPIO_AF0_MCO;
  HAL_GPIO_Init(DCMI_MCLK_GPIO_Port, &GPIO_InitStruct);

  /*Configure GPIO pin : WAKEUP_Pin */
  GPIO_InitStruct.Pin = WAKEUP_Pin;
  GPIO_InitStruct.Mode = GPIO_MODE_IT_RISING_FALLING;
  GPIO_InitStruct.Pull = GPIO_NOPULL;
  HAL_GPIO_Init(WAKEUP_GPIO_Port, &GPIO_InitStruct);

  /*Configure GPIO pin : SPI1_CS_Pin */
  GPIO_InitStruct.Pin = SPI1_CS_Pin;
  GPIO_InitStruct.Mode = GPIO_MODE_INPUT;
  GPIO_InitStruct.Pull = GPIO_NOPULL;
  HAL_GPIO_Init(SPI1_CS_GPIO_Port, &GPIO_InitStruct);

  /*Configure GPIO pins : PC10 PC12 */
  GPIO_InitStruct.Pin = GPIO_PIN_10|GPIO_PIN_12;
  GPIO_InitStruct.Mode = GPIO_MODE_ANALOG;
  GPIO_InitStruct.Pull = GPIO_NOPULL;
  HAL_GPIO_Init(GPIOC, &GPIO_InitStruct);

  /*Configure GPIO pin : PD2 */
  GPIO_InitStruct.Pin = GPIO_PIN_2;
  GPIO_InitStruct.Mode = GPIO_MODE_ANALOG;
  GPIO_InitStruct.Pull = GPIO_NOPULL;
  HAL_GPIO_Init(GPIOD, &GPIO_InitStruct);

  /*Configure GPIO pin : PH3 */
  GPIO_InitStruct.Pin = GPIO_PIN_3;
  GPIO_InitStruct.Mode = GPIO_MODE_ANALOG;
  GPIO_InitStruct.Pull = GPIO_NOPULL;
  HAL_GPIO_Init(GPIOH, &GPIO_InitStruct);

  /* EXTI interrupt init*/
  HAL_NVIC_SetPriority(EXTI9_IRQn, 0, 0);
  HAL_NVIC_EnableIRQ(EXTI9_IRQn);

  HAL_NVIC_SetPriority(EXTI13_IRQn, 0, 0);
  HAL_NVIC_EnableIRQ(EXTI13_IRQn);

}

void HAL_TIM_PeriodElapsedCallback(TIM_HandleTypeDef *htim)
{
  if (htim->Instance == TIM17)
  {
    HAL_IncTick();
  }
}

void Error_Handler(void)
{
  __disable_irq();
  while (1)
  {
  }
}
